# LPC176x5x register map
File version: 0.2
CPU: CM3 r0p0, little endian, MPU, no FPU, 5 interrupt priority bits
Registers are 32-bit, read-write, reset 0x0 unless marked. A register's access mark holds for its fields unless they carry their own. Offsets are from the block's base; [hi:lo] are bit positions; {n}, {i} and the like mark numbered series.

## DAC — Digital-to-Analog Converter (DAC)
Base 0x4008C000
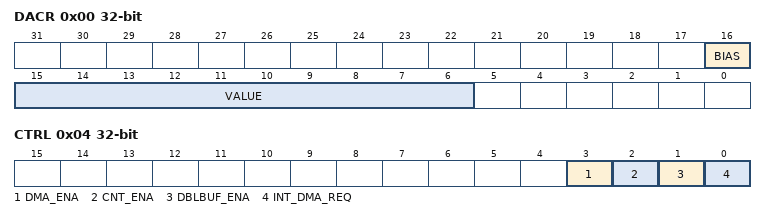
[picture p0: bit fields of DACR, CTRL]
0x00 DACR — D/A Converter Register. This register contains the digital value to be converted to analog and a power control bit.
  [16] BIAS — Settling time The settling times noted in the description of the BIAS bit are valid for a capacitance load on the DAC_OUT pin not exceeding 100 pF. A load impedance value greater than that value will cause settling time longer than the specified time. One or more graphs of load impedance vs. settling time will be included in the final data sheet.
    0=FAST (The settling time of the DAC is 1 us max, and the maximum current is 700 uA. This allows a maximum update rate of 1 MHz.); 1=SLOW (The settling time of the DAC is 2.5 us and the maximum current is 350 uA. This allows a maximum update rate of 400 kHz.)
  [15:6] VALUE — After the selected settling time after this field is written with a new VALUE, the voltage on the DAC_OUT pin (with respect to VSSA) is VALUE x ((VREFP - V REFN)/1024) + VREFN.
0x04 CTRL — DAC Control register. This register controls DMA and timer operation.
  [3] DMA_ENA — DMA access
    0=DISABLE; 1=ENABLE_DMA_BURST_RE (Enable. DMA Burst Request Input 7 is enabled for the DAC (see Table 672).)
  [2] CNT_ENA — Time-out counter operation
    0=DISABLE; 1=ENABLE
  [1] DBLBUF_ENA — Double buffering
    0=DISABLE; 1=ENABLE_WHEN_THIS_BI (Enable. When this bit and the CNT_ENA bit are both set, the double-buffering feature in the DACR register will be enabled. Writes to the DACR register are written to a pre-buffer and then transferred to the DACR on the next time-out of the counter.)
  [0] INT_DMA_REQ — DMA interrupt request
    0=CLEAR_ON_ANY_WRITE_T (Clear on any write to the DACR register.); 1=SET_BY_HARDWARE_WHEN (Set by hardware when the timer times out.)
0x08 CNTVAL — DAC Counter Value register. This register contains the reload value for the DAC DMA/Interrupt timer.
  [15:0] VALUE — 16-bit reload value for the DAC interrupt/DMA timer.

## RITIMER — Repetitive Interrupt Timer (RIT)
Base 0x400B0000
0x00 COMPVAL reset 0xFFFFFFFF — Compare register
  [31:0] RICOMP — Compare register. Holds the compare value which is compared to the counter.
0x04 MASK — Mask register. This register holds the 32-bit mask value. A 1 written to any bit will force a compare on the corresponding bit of the counter and compare register.
  [31:0] RIMASK — Mask register. This register holds the 32-bit mask value. A one written to any bit overrides the result of the comparison for the corresponding bit of the counter and compare register (causes the comparison of the register bits to be always true).
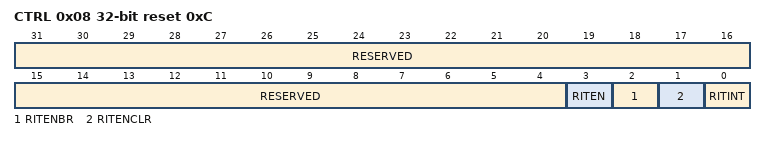
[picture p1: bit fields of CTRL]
0x08 CTRL reset 0xC — Control register.
  [31:4] RESERVED — Reserved, user software should not write ones to reserved bits. The value read from a reserved bit is not defined.
  [3] RITEN — Timer enable.
    1=TIMER_ENABLED_THIS_ (Timer enabled. This can be overruled by a debug halt if enabled in bit 2.); 0=TIMER_DISABLED_
  [2] RITENBR — Timer enable for debug
    1=THE_TIMER_IS_HALTED_ (The timer is halted when the processor is halted for debugging.); 0=DEBUG_HAS_NO_EFFECT_ (Debug has no effect on the timer operation.)
  [1] RITENCLR — Timer enable clear
    1=THE_TIMER_WILL_BE_CL (The timer will be cleared to 0 whenever the counter value equals the masked compare value specified by the contents of RICOMPVAL and RIMASK registers. This will occur on the same clock that sets the interrupt flag.); 0=THE_TIMER_WILL_NOT_B (The timer will not be cleared to 0.)
  [0] RITINT — Interrupt flag
    1=THIS_BIT_IS_SET_TO_1 (This bit is set to 1 by hardware whenever the counter value equals the masked compare value specified by the contents of RICOMPVAL and RIMASK registers. Writing a 1 to this bit will clear it to 0. Writing a 0 has no effect.); 0=THE_COUNTER_VALUE_DO (The counter value does not equal the masked compare value.)
0x0C COUNTER — 32-bit counter
  [31:0] RICOUNTER — 32-bit up counter. Counts continuously unless RITEN bit in RICTRL register is cleared or debug mode is entered (if enabled by the RITNEBR bit in RICTRL). Can be loaded to any value in software.

## GPIO — General Purpose I/O
Base 0x2009C000
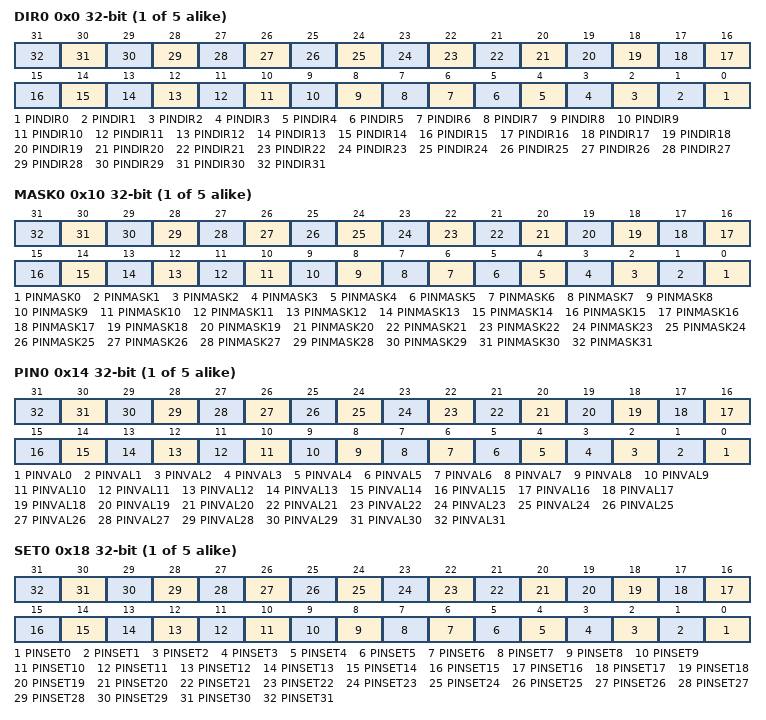
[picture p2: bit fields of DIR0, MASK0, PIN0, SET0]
{0x0+0x20*i} DIR{i} (i=0..4) — GPIO Port Direction control register.
  [n] PINDIR{n} (n=0..31) — Fast GPIO Direction PORTx control bits. Bit 0 in DIRx controls pin Px[0], bit 31 in DIRx controls pin Px[31]. 0 = Controlled pin is input. 1 = Controlled pin is output.
{0x10+0x20*i} MASK{i} (i=0..4) — Mask register for Port.
  [n] PINMASK{n} (n=0..31) — Fast GPIO physical pin access control. 0 = Controlled pin is affected by writes to the port's SETx, CLRx, and PINx register(s). Current state of the pin can be read from the PINx register. 1 = Controlled pin is not affected by writes into the port's SETx, CLRx and PINx register(s). When the PINx register is read, this bit will not be updated with the state of the physical pin.
{0x14+0x20*i} PIN{i} (i=0..4) — Port Pin value register using FIOMASK.
  [n] PINVAL{n} (n=0..31) — Fast GPIO output value Set bits. Bit 0 in PINx corresponds to pin Px[0], bit 31 in PINx corresponds to pin Px[31]. 0 = Controlled pin output is set to LOW. 1 = Controlled pin output is set to HIGH.
{0x18+0x20*i} SET{i} (i=0..4) — Port Output Set register using FIOMASK.
  [n] PINSET{n} (n=0..31) — Fast GPIO output value Set bits. Bit 0 in SETx controls pin Px[0], bit 31 in SETx controls pin Px[31]. 0 = Controlled pin output is unchanged. 1 = Controlled pin output is set to HIGH.
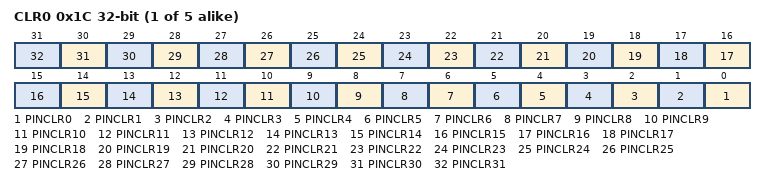
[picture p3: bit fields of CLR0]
{0x1C+0x20*i} CLR{i} (i=0..4) wo — Port Output Clear register using FIOMASK.
  [n] PINCLR{n} (n=0..31) — Fast GPIO output value Clear bits. Bit 0 in CLRx controls pin Px[0], bit 31 in CLRx controls pin Px[31]. 0 = Controlled pin output is unchanged. 1 = Controlled pin output is set to LOW.
